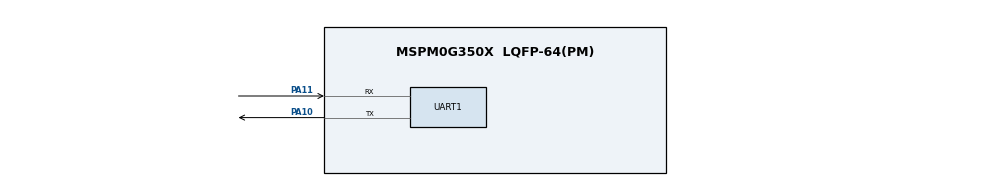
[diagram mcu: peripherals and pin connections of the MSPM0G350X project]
/**
 * @cliArgs --device "MSPM0G350X" --package "LQFP-64(PM)" --part "Default" --product "mspm0_sdk@2.01.00.03"
 * @versions {"tool":"1.20.0+3587"}
 */

/**
 * Import the modules used in this configuration.
 */
const GPIO   = scripting.addModule("/ti/driverlib/GPIO", {}, false);
const GPIO1  = GPIO.addInstance();
const SYSCTL = scripting.addModule("/ti/driverlib/SYSCTL");
const TIMER  = scripting.addModule("/ti/driverlib/TIMER", {}, false);
const TIMER1 = TIMER.addInstance();
const UART   = scripting.addModule("/ti/driverlib/UART", {}, false);
const UART1  = UART.addInstance();

/**
 * Write custom configuration values to the imported modules.
 */
GPIO1.$name                          = "GPIO_Ultrasonic";
GPIO1.associatedPins.create(2);
GPIO1.associatedPins[0].$name        = "PIN_Trig";
GPIO1.associatedPins[0].assignedPort = "PORTA";
GPIO1.associatedPins[0].assignedPin  = "12";
GPIO1.associatedPins[1].$name        = "PIN_Echo";
GPIO1.associatedPins[1].direction    = "INPUT";
GPIO1.associatedPins[1].assignedPort = "PORTA";
GPIO1.associatedPins[1].assignedPin  = "13";

const Board = scripting.addModule("/ti/driverlib/Board", {}, false);

SYSCTL.forceDefaultClkConfig = true;

TIMER1.$name            = "TIMER_Ultrasonic";
TIMER1.timerMode        = "ONE_SHOT_UP";
TIMER1.interrupts       = ["LOAD"];
TIMER1.timerClkPrescale = 32;
TIMER1.timerPeriod      = "25ms";

UART1.$name                    = "UART_0";
UART1.peripheral.rxPin.$assign = "PA11";
UART1.peripheral.txPin.$assign = "PA10";
UART1.txPinConfig.$name        = "ti_driverlib_gpio_GPIOPinGeneric0";
UART1.rxPinConfig.$name        = "ti_driverlib_gpio_GPIOPinGeneric1";

/**
 * Pinmux solution for unlocked pins/peripherals. This ensures that minor changes to the automatic solver in a future
 * version of the tool will not impact the pinmux you originally saw.  These lines can be completely deleted in order to
 * re-solve from scratch.
 */
GPIO1.associatedPins[0].pin.$suggestSolution = "PA12";
GPIO1.associatedPins[1].pin.$suggestSolution = "PA13";
Board.peripheral.$suggestSolution            = "DEBUGSS";
Board.peripheral.swclkPin.$suggestSolution   = "PA20";
Board.peripheral.swdioPin.$suggestSolution   = "PA19";
SYSCTL.peripheral.$suggestSolution           = "SYSCTL";
TIMER1.peripheral.$suggestSolution           = "TIMA0";
UART1.peripheral.$suggestSolution            = "UART0";
